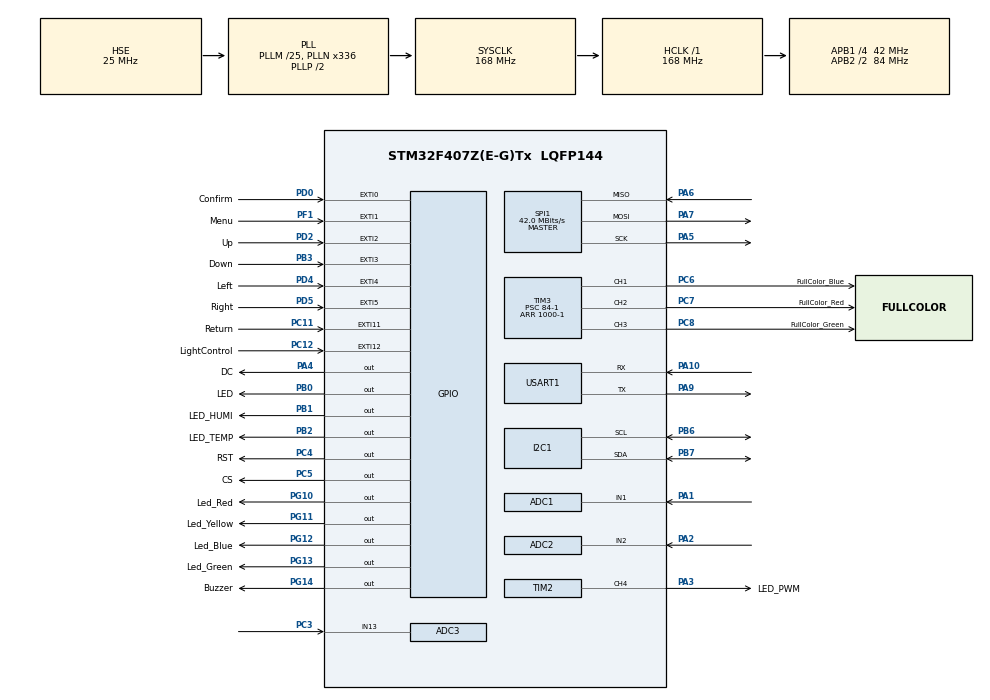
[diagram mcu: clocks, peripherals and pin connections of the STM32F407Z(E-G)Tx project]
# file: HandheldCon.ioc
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ADC1.Channel-0\#ChannelRegularConversion=ADC_CHANNEL_1
ADC1.ContinuousConvMode=ENABLE
ADC1.NbrOfConversionFlag=1
ADC1.Rank-0\#ChannelRegularConversion=1
ADC1.SamplingTime-0\#ChannelRegularConversion=ADC_SAMPLETIME_3CYCLES
ADC1.master=1
ADC2.Channel-0\#ChannelRegularConversion=ADC_CHANNEL_2
ADC2.ContinuousConvMode=ENABLE
ADC2.NbrOfConversionFlag=1
ADC2.Rank-0\#ChannelRegularConversion=1
ADC2.SamplingTime-0\#ChannelRegularConversion=ADC_SAMPLETIME_3CYCLES
ADC3.Channel-0\#ChannelRegularConversion=ADC_CHANNEL_13
ADC3.ContinuousConvMode=ENABLE
ADC3.NbrOfConversionFlag=1
ADC3.Rank-0\#ChannelRegularConversion=1
ADC3.SamplingTime-0\#ChannelRegularConversion=ADC_SAMPLETIME_3CYCLES
Mcu.Family=STM32F4
Mcu.Name=STM32F407Z(E-G)Tx
Mcu.Package=LQFP144
NVIC.EXTI0_IRQn=true\:0\:0\:false\:false\:true\:true\:true
NVIC.EXTI15_10_IRQn=true\:0\:0\:false\:false\:true\:true\:true
NVIC.EXTI1_IRQn=true\:0\:0\:false\:false\:true\:true\:true
NVIC.EXTI2_IRQn=true\:0\:0\:false\:false\:true\:true\:true
NVIC.EXTI3_IRQn=true\:0\:0\:false\:false\:true\:true\:true
NVIC.EXTI4_IRQn=true\:0\:0\:false\:false\:true\:true\:true
NVIC.EXTI9_5_IRQn=true\:0\:0\:false\:false\:true\:true\:true
NVIC.PriorityGroup=NVIC_PRIORITYGROUP_4
PA1.Signal=ADCx_IN1
PA10.Mode=Asynchronous
PA10.Signal=USART1_RX
PA13.Mode=Serial_Wire
PA13.Signal=SYS_JTMS-SWDIO
PA14.Mode=Serial_Wire
PA14.Signal=SYS_JTCK-SWCLK
PA2.Signal=ADCx_IN2
PA3.GPIO_Label=LED_PWM
PA3.Signal=S_TIM2_CH4
PA4.GPIO_Label=DC
PA4.Signal=GPIO_Output
PA5.Mode=Full_Duplex_Master
PA5.Signal=SPI1_SCK
PA6.Mode=Full_Duplex_Master
PA6.Signal=SPI1_MISO
PA7.Mode=Full_Duplex_Master
PA7.Signal=SPI1_MOSI
PA9.Mode=Asynchronous
PA9.Signal=USART1_TX
PB0.GPIO_Label=LED
PB0.GPIO_Speed=GPIO_SPEED_FREQ_VERY_HIGH
PB0.PinState=GPIO_PIN_SET
PB0.Signal=GPIO_Output
PB1.GPIO_Label=LED_HUMI
PB1.PinState=GPIO_PIN_SET
PB1.Signal=GPIO_Output
PB2.GPIO_Label=LED_TEMP
PB2.PinState=GPIO_PIN_SET
PB2.Signal=GPIO_Output
PB3.GPIO_Label=Down
PB3.GPIO_PuPd=GPIO_PULLUP
PB3.Signal=GPXTI3
PB6.Mode=I2C
PB6.Signal=I2C1_SCL
PB7.Mode=I2C
PB7.Signal=I2C1_SDA
PC11.GPIO_Label=Return
PC11.GPIO_PuPd=GPIO_PULLUP
PC11.Signal=GPXTI11
PC12.GPIO_Label=LightControl
PC12.GPIO_PuPd=GPIO_PULLUP
PC12.Signal=GPXTI12
PC3.Signal=ADCx_IN13
PC4.GPIO_Label=RST
PC4.GPIO_Speed=GPIO_SPEED_FREQ_VERY_HIGH
PC4.Signal=GPIO_Output
PC5.GPIO_Label=CS
PC5.GPIO_Speed=GPIO_SPEED_FREQ_VERY_HIGH
PC5.Signal=GPIO_Output
PC6.GPIO_Label=FullColor_Blue
PC6.Signal=S_TIM3_CH1
PC7.GPIO_Label=FullColor_Red
PC7.Signal=S_TIM3_CH2
PC8.GPIO_Label=FullColor_Green
PC8.Signal=S_TIM3_CH3
PD0.GPIO_Label=Confirm
PD0.GPIO_PuPd=GPIO_PULLUP
PD0.Signal=GPXTI0
PD2.GPIO_Label=Up
PD2.GPIO_PuPd=GPIO_PULLUP
PD2.Signal=GPXTI2
PD4.GPIO_Label=Left
PD4.GPIO_PuPd=GPIO_PULLUP
PD4.Signal=GPXTI4
PD5.GPIO_Label=Right
PD5.GPIO_PuPd=GPIO_PULLUP
PD5.Signal=GPXTI5
PF1.GPIO_Label=Menu
PF1.GPIO_PuPd=GPIO_PULLUP
PF1.Signal=GPXTI1
PG10.GPIO_Label=Led_Red
PG10.GPIO_Speed=GPIO_SPEED_FREQ_LOW
PG10.PinState=GPIO_PIN_SET
PG10.Signal=GPIO_Output
PG11.GPIO_Label=Led_Yellow
PG11.PinState=GPIO_PIN_SET
PG11.Signal=GPIO_Output
PG12.GPIO_Label=Led_Blue
PG12.PinState=GPIO_PIN_SET
PG12.Signal=GPIO_Output
PG13.GPIO_Label=Led_Green
PG13.PinState=GPIO_PIN_SET
PG13.Signal=GPIO_Output
PG14.GPIO_Label=Buzzer
PG14.GPIO_ModeDefaultOutputPP=GPIO_MODE_OUTPUT_OD
PG14.PinState=GPIO_PIN_SET
PG14.Signal=GPIO_Output
PH0-OSC_IN.Mode=HSE-External-Clock-Source
PH0-OSC_IN.Signal=RCC_OSC_IN
PH1-OSC_OUT.Mode=HSE-External-Clock-Source
PH1-OSC_OUT.Signal=RCC_OSC_OUT
ProjectManager.HeapSize=0x200
ProjectManager.StackSize=0x400
ProjectManager.TargetToolchain=MDK-ARM V5.27
RCC.48MHZClocksFreq_Value=48000000
RCC.AHBFreq_Value=168000000
RCC.APB1CLKDivider=RCC_HCLK_DIV4
RCC.APB1Freq_Value=42000000
RCC.APB1TimFreq_Value=84000000
RCC.APB2CLKDivider=RCC_HCLK_DIV2
RCC.APB2Freq_Value=84000000
RCC.APB2TimFreq_Value=168000000
RCC.CortexFreq_Value=168000000
RCC.HCLKFreq_Value=168000000
RCC.HSE_VALUE=25000000
RCC.HSI_VALUE=16000000
RCC.LSE_VALUE=32768
RCC.PLLM=25
RCC.PLLN=336
RCC.PLLQ=7
RCC.PLLSourceVirtual=RCC_PLLSOURCE_HSE
RCC.SYSCLKFreq_VALUE=168000000
RCC.SYSCLKSource=RCC_SYSCLKSOURCE_PLLCLK
RCC.VCOOutputFreq_Value=336000000
SH.ADCx_IN1.0=ADC1_IN1,IN1
SH.ADCx_IN13.0=ADC3_IN13,IN13
SH.ADCx_IN2.0=ADC2_IN2,IN2
SH.S_TIM2_CH4.0=TIM2_CH4,PWM Generation4 CH4
SH.S_TIM3_CH1.0=TIM3_CH1,PWM Generation1 CH1
SH.S_TIM3_CH2.0=TIM3_CH2,PWM Generation2 CH2
SH.S_TIM3_CH3.0=TIM3_CH3,PWM Generation3 CH3
SPI1.BaudRatePrescaler=SPI_BAUDRATEPRESCALER_2
SPI1.CLKPhase=SPI_PHASE_2EDGE
SPI1.CLKPolarity=SPI_POLARITY_HIGH
SPI1.CalculateBaudRate=42.0 MBits/s
SPI1.Direction=SPI_DIRECTION_2LINES
SPI1.Mode=SPI_MODE_MASTER
SPI1.VirtualType=VM_MASTER
TIM2.Channel-PWM\ Generation4\ CH4=TIM_CHANNEL_4
TIM2.Period=1000-1
TIM2.Prescaler=84-1
TIM2.Pulse-PWM\ Generation4\ CH4=0
TIM3.Channel-PWM\ Generation1\ CH1=TIM_CHANNEL_1
TIM3.Channel-PWM\ Generation2\ CH2=TIM_CHANNEL_2
TIM3.Channel-PWM\ Generation3\ CH3=TIM_CHANNEL_3
TIM3.Period=1000-1
TIM3.Prescaler=84-1
TIM3.Pulse-PWM\ Generation1\ CH1=500
TIM3.Pulse-PWM\ Generation2\ CH2=500
TIM3.Pulse-PWM\ Generation3\ CH3=500
USART1.VirtualMode=VM_ASYNC
VP_RNG_VS_RNG.Mode=RNG_Activate
VP_TIM2_VS_ClockSourceINT.Mode=Internal
VP_TIM3_VS_ClockSourceINT.Mode=Internal
board=custom

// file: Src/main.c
/* USER CODE BEGIN Header */
/**
  ******************************************************************************
  * @file           : main.c
  * @brief          : Main program body
  ******************************************************************************
  * @attention
  *
  * <h2><center>&copy; Copyright (c) 2019 STMicroelectronics.
  * All rights reserved.</center></h2>
  *
  * This software component is licensed by ST under BSD 3-Clause license,
  * the "License"; You may not use this file except in compliance with the
  * License. You may obtain a copy of the License at:
  *                        opensource.org/licenses/BSD-3-Clause
  *
  ******************************************************************************
  */
/* USER CODE END Header */

#include "main.h"
#include "adc.h"
#include "i2c.h"
#include "rng.h"
#include "spi.h"
#include "tim.h"
#include "usart.h"
#include "gpio.h"

/* USER CODE BEGIN Includes */
#include "User_main.h"
/* USER CODE END Includes */

void SystemClock_Config(void);

int main(void)
{

  /* MCU Configuration--------------------------------------------------------*/

  /* Reset of all peripherals, Initializes the Flash interface and the Systick. */
  HAL_Init();

  /* Configure the system clock */
  SystemClock_Config();

  /* Initialize all configured peripherals */
  MX_GPIO_Init();
  MX_SPI1_Init();
  MX_RNG_Init();
  MX_ADC1_Init();
  MX_ADC2_Init();
  MX_I2C1_Init();
  MX_TIM2_Init();
  MX_TIM3_Init();
  MX_USART1_UART_Init();
  MX_ADC3_Init();
  /* USER CODE BEGIN 2 */
	Lcd_Init();
	Lcd_Clear(WHITE);
  /* USER CODE END 2 */

  /* Infinite loop */
  /* USER CODE BEGIN WHILE */
  while (1)
  {
		User_main();
    /* USER CODE END WHILE */

  }
}

void SystemClock_Config(void)
{
  RCC_OscInitTypeDef RCC_OscInitStruct = {0};
  RCC_ClkInitTypeDef RCC_ClkInitStruct = {0};

  /** Configure the main internal regulator output voltage
  */
  __HAL_RCC_PWR_CLK_ENABLE();
  __HAL_PWR_VOLTAGESCALING_CONFIG(PWR_REGULATOR_VOLTAGE_SCALE1);
  /** Initializes the CPU, AHB and APB busses clocks
  */
  RCC_OscInitStruct.OscillatorType = RCC_OSCILLATORTYPE_HSE;
  RCC_OscInitStruct.HSEState = RCC_HSE_BYPASS;
  RCC_OscInitStruct.PLL.PLLState = RCC_PLL_ON;
  RCC_OscInitStruct.PLL.PLLSource = RCC_PLLSOURCE_HSE;
  RCC_OscInitStruct.PLL.PLLM = 25;
  RCC_OscInitStruct.PLL.PLLN = 336;
  RCC_OscInitStruct.PLL.PLLP = RCC_PLLP_DIV2;
  RCC_OscInitStruct.PLL.PLLQ = 7;
  if (HAL_RCC_OscConfig(&RCC_OscInitStruct) != HAL_OK)
  {
    Error_Handler();
  }
  /** Initializes the CPU, AHB and APB busses clocks
  */
  RCC_ClkInitStruct.ClockType = RCC_CLOCKTYPE_HCLK|RCC_CLOCKTYPE_SYSCLK
                              |RCC_CLOCKTYPE_PCLK1|RCC_CLOCKTYPE_PCLK2;
  RCC_ClkInitStruct.SYSCLKSource = RCC_SYSCLKSOURCE_PLLCLK;
  RCC_ClkInitStruct.AHBCLKDivider = RCC_SYSCLK_DIV1;
  RCC_ClkInitStruct.APB1CLKDivider = RCC_HCLK_DIV4;
  RCC_ClkInitStruct.APB2CLKDivider = RCC_HCLK_DIV2;

  if (HAL_RCC_ClockConfig(&RCC_ClkInitStruct, FLASH_LATENCY_5) != HAL_OK)
  {
    Error_Handler();
  }
}

void Error_Handler(void)
{
}

/************************ (C) COPYRIGHT STMicroelectronics *****END OF FILE****/
